# YTM32B1MD2 register map
Vendor: YTMicro; File version: 1.0
CPU: CM33 r0p4, little endian, MPU, FPU, 2 interrupt priority bits
Registers are 32-bit, read-write, reset 0x0 unless marked. A register's access mark holds for its fields unless they carry their own. Offsets are from the block's base; [hi:lo] are bit positions; {n}, {i} and the like mark numbered series.

## CMU0 — Clock monitor unit
Base 0x40076000; register names take the prefix CMU0_
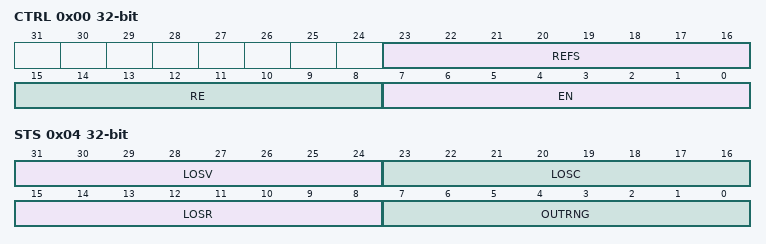
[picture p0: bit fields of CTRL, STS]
0x00 CTRL — System Clock Unit Clock Monitor Unit control register. Refer to Chip-specific chapter for Channels Information.
  [23:16] REFS — The reference clock of each CMU channel can be configured independently. For CMU channel which monitor FXOSC clock, only SIRC clock can be used as reference clock. For other channels, reference clock can select between SIRC clock and FXOSC clock. For each bit of CMU_REFS : 0b - The indexed channel select SIRC clock as reference clock; 1b - The indexed channel select FXOSC clock as reference clock.
  [15:8] RE — The reset of each CMU channel can be configured independently. For each bit of CMU_RE: 0b - Interrupt is generated when the indexed channel monitored clock is out of range; 1b - Reset is generated when the indexed channel monitored clock is out of range.
  [7:0] EN — CMU has up to 8 channels to monitor internal clocks. Software can configure a CMU channel only when that channel is disabled. For CMU channel n, please configure CTRL.REFS[n], CTRL.RE[n], CMPn, REFCNTTGTn before set CTRL.EN[n] high. Each CMU channel can be enable or disabled independently. For each bit of CMU_EN: 0b - The indexed channel is disabled; 1b - The indexed channel is enabled.
0x04 STS — System Clock Unit Clock Monitor Unit status register. This register is reset by Power-on Reset.
  [31:24] LOSV — CMU_LOSV[n]=1 (n=0~7) means channel n loss of monitored clock valid in CLKVLDDLY selected time slice . This register is reset by Power-on Reset.
  [23:16] LOSC — CMU_LOSC[n]=1 (n=0~7) means channel n loss of monitored clock. This register is reset by Power-on Reset.
  [15:8] LOSR — CMU_LOSR[n]=1 (n=0~7) means channel n loss of reference clock. This register is reset by Power-on Reset.
  [7:0] OUTRNG — CMU_OUTRNG[n]=1 (n=0~7) means channel n monitored clock out of range. This register is reset by Power-on Reset.
{0x8+8i} CMP{i}_HIGH reset 0xFFFF (i=0..7) — Clock Monitor High Comparison Value Register.
  [15:0] VAL — Monitored clock counter will compare with this register when reference clock counter equals REFCNTTGT. If monitored clock counter larger than this register, CMU initiate an out-of-range event.
{0xC+8i} CMP{i}_LOW (i=0..7) — Clock Monitor Low Comparison Value Register
  [15:0] VAL — Monitored clock counter will compare with this register when reference clock counter equals REFCNTTGT. If monitored clock counter less than this register, CMU initiate an out-of-range event.
{0x48+4i} REFCNTTGT{i} reset 0x7F (i=0..7) — Reference Clock Counter Target Value Register for Each CMU Channel
  [7:0] VAL — The sample window of CMU channel n is (REFCNTTGTn+1) reference clock cycles. Internal monitered clock counter value is campared to CMP.HIGH and CMP.LOW at end of each sample window.
{0x8C+4i} CLKVLDDLY{i} reset 0xF (i=0..7)
  [3:0] VAL — Each CMU channel optinally support a detector which detecting over-time delay between monitored clock enable and monitored clock valid. CMU channel n starts counting the delay time when: - CMU Channel n has monitored clock valid detector - And CTRL.EN[n]=1 - And CMU channel n's reference clock is enabled - And CMU channel n's monitored clock is enabled The monitored clock valid need to come in time limitation configured by CLKVLDDLYn, or a clock-valid-miss event will initiate. Refer to Chip-specific Information for maximum delay time of Monitored Clock Valid of each CMU channel.
    {v}=The clock valid needs to come in {v+1}/16 of maximum delay time after clock enabled (v=0..14); 15=The clock valid needs to come in maximum delay time after clock enabled
